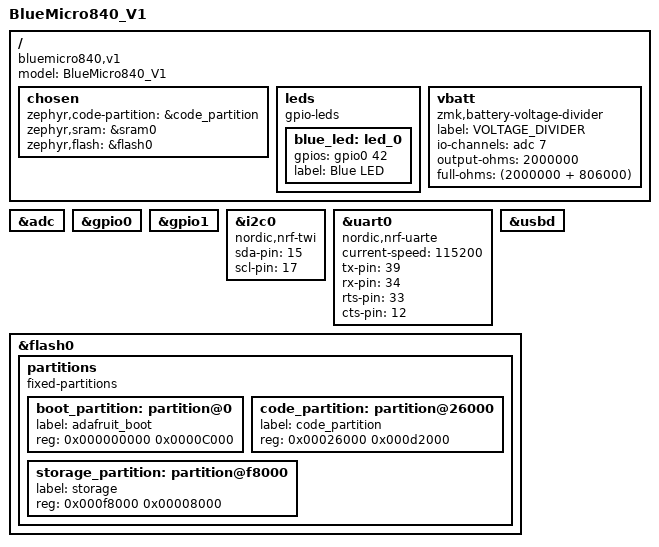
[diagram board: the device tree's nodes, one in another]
/*
 * Copyright (c) 2020 Pete Johanson, Derek Schmell
 *
 * SPDX-License-Identifier: MIT
 */

/dts-v1/;
#include <nordic/nrf52840_qiaa.dtsi>
#include "arduino_pro_micro_pins.dtsi"

/ {
	model = "BlueMicro840_V1";
	compatible = "bluemicro840,v1";

	chosen {
		zephyr,code-partition = &code_partition;
		// zephyr,console = &uart0;
		//zephyr,bt-mon-uart = &uart0;
		//zephyr,bt-c2h-uart = &uart0;
		zephyr,sram = &sram0;
		zephyr,flash = &flash0;
	};

	leds {
		compatible = "gpio-leds";
		blue_led: led_0 {
			gpios = <&gpio0 42 GPIO_ACTIVE_HIGH>;
			label = "Blue LED";
		};
	};

	vbatt {
		compatible = "zmk,battery-voltage-divider";
		label = "VOLTAGE_DIVIDER";
		io-channels = <&adc 7>;
		output-ohms = <2000000>;
		full-ohms = <(2000000 + 806000)>;
	};

};

&adc {
	status = "okay";
};

&gpio0 {
	status = "okay";
};

&gpio1 {
	status = "okay";
};

&i2c0 {
	compatible = "nordic,nrf-twi";
	sda-pin = <15>;
	scl-pin = <17>;
};

&uart0 {
	compatible = "nordic,nrf-uarte";
	status = "okay";
	current-speed = <115200>;
	tx-pin = <39>;
	rx-pin = <34>;
	rts-pin = <33>;
	cts-pin = <12>;
};

&usbd {
	status = "okay";
};


&flash0 {
	/*
	 * For more information, see:
	 * http://docs.zephyrproject.org/latest/devices/dts/flash_partitions.html
	 */
	partitions {
		compatible = "fixed-partitions";
		#address-cells = <1>;
		#size-cells = <1>;

		boot_partition: partition@0 {
			label = "adafruit_boot";
			reg = <0x000000000 0x0000C000>;
		};
		code_partition: partition@26000 {
			label = "code_partition";
			reg = <0x00026000 0x000d2000>;
		};

		/*
		 * The flash starting at 0x000f8000 and ending at
		 * 0x000fffff is reserved for use by the application.
		 */

		/*
		 * Storage partition will be used by FCB/LittleFS/NVS
		 * if enabled.
		 */
		storage_partition: partition@f8000 {
			label = "storage";
			reg = <0x000f8000 0x00008000>;
		};
	};
};
